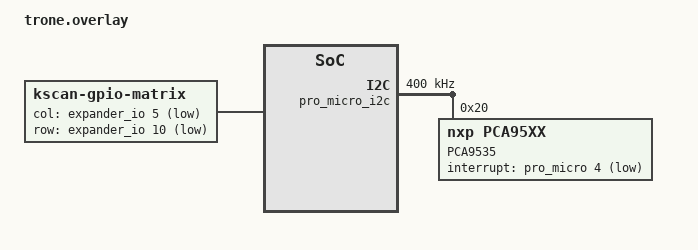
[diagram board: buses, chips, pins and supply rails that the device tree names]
/*
 * Copyright (c) 2021 The ZMK Contributors
 *
 * SPDX-License-Identifier: MIT
 */

#include <dt-bindings/zmk/matrix_transform.h>

/ {
    chosen {
        zmk,kscan = &kscan0;
        zmk,matrix_transform = &default_transform;
    };

    default_transform: keymap_transform_0 {
        compatible = "zmk,matrix-transform";
        columns = <1>;
        rows = <1>;
        map = <
        RC(0,0)
        >;
    };

    kscan0: kscan_0 {
        compatible = "zmk,kscan-gpio-matrix";
        label = "KSCAN";
        diode-direction = "row2col";
        debounce-press-ms = <20>;
        debounce-release-ms = <20>;

        col-gpios
            = <&expander_io 5 GPIO_ACTIVE_LOW> // external pullup
            ;

        row-gpios
            = <&expander_io 10 GPIO_ACTIVE_LOW>
            ;
    };

};

&pro_micro_i2c {
    status = "okay";
    clock-frequency = <I2C_BITRATE_FAST>;
    expander_io: pca95xx@20 {
        compatible = "nxp,pca95xx";
        status = "okay";
        gpio-controller;
        reg = <0x20>;
        label = "PCA9535";
        interrupt-gpios = <&pro_micro 4 GPIO_ACTIVE_LOW>;
        #gpio-cells = <2>;
        ngpios = <16>;
    };
};
